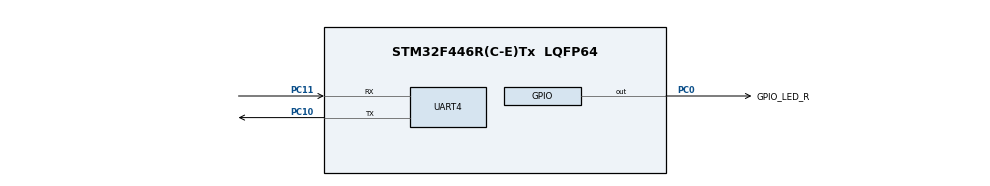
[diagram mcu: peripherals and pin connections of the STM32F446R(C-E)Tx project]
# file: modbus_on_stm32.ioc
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Dma.Request0=UART4_RX
Dma.Request1=UART4_TX
Dma.UART4_RX.0.Direction=DMA_PERIPH_TO_MEMORY
Dma.UART4_RX.0.FIFOMode=DMA_FIFOMODE_DISABLE
Dma.UART4_RX.0.Instance=DMA1_Stream2
Dma.UART4_RX.0.MemDataAlignment=DMA_MDATAALIGN_BYTE
Dma.UART4_RX.0.MemInc=DMA_MINC_ENABLE
Dma.UART4_RX.0.Mode=DMA_NORMAL
Dma.UART4_RX.0.PeriphDataAlignment=DMA_PDATAALIGN_BYTE
Dma.UART4_RX.0.PeriphInc=DMA_PINC_DISABLE
Dma.UART4_RX.0.Priority=DMA_PRIORITY_VERY_HIGH
Dma.UART4_TX.1.Direction=DMA_MEMORY_TO_PERIPH
Dma.UART4_TX.1.FIFOMode=DMA_FIFOMODE_DISABLE
Dma.UART4_TX.1.Instance=DMA1_Stream4
Dma.UART4_TX.1.MemDataAlignment=DMA_MDATAALIGN_BYTE
Dma.UART4_TX.1.MemInc=DMA_MINC_ENABLE
Dma.UART4_TX.1.Mode=DMA_NORMAL
Dma.UART4_TX.1.PeriphDataAlignment=DMA_PDATAALIGN_BYTE
Dma.UART4_TX.1.PeriphInc=DMA_PINC_DISABLE
Dma.UART4_TX.1.Priority=DMA_PRIORITY_VERY_HIGH
Mcu.Family=STM32F4
Mcu.Name=STM32F446R(C-E)Tx
Mcu.Package=LQFP64
NVIC.DMA1_Stream2_IRQn=true\:0\:0\:false\:false\:true\:false\:true\:true
NVIC.DMA1_Stream4_IRQn=true\:0\:0\:false\:false\:true\:false\:true\:true
NVIC.PriorityGroup=NVIC_PRIORITYGROUP_4
NVIC.TIM1_UP_TIM10_IRQn=true\:15\:0\:true\:false\:true\:true\:true\:true
NVIC.UART4_IRQn=true\:0\:0\:false\:false\:true\:true\:true\:true
PC0.GPIO_Label=GPIO_LED_R
PC0.Signal=GPIO_Output
PC10.Mode=Asynchronous
PC10.Signal=UART4_TX
PC11.Mode=Asynchronous
PC11.Signal=UART4_RX
PH0-OSC_IN.Mode=HSE-External-Oscillator
PH0-OSC_IN.Signal=RCC_OSC_IN
PH1-OSC_OUT.Mode=HSE-External-Oscillator
PH1-OSC_OUT.Signal=RCC_OSC_OUT
ProjectManager.HeapSize=0x200
ProjectManager.StackSize=0x400
ProjectManager.TargetToolchain=MDK-ARM V5.32
RCC.CortexFreq_Value=16000000
RCC.USBFreq_Value=96000000
RCC.VCOOutputFreq_Value=192000000
TIM1.Period=4999
TIM1.Prescaler=1599
UART4.VirtualMode=Asynchronous
VP_TIM1_VS_ClockSourceINT.Mode=Internal
board=custom

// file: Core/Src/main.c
/* USER CODE BEGIN Header */
/**
  ******************************************************************************
  * @file           : main.c
  * @brief          : Main program body
  ******************************************************************************
  * @attention
  *
  * Copyright (c) 2024 STMicroelectronics.
  * All rights reserved.
  *
  * This software is licensed under terms that can be found in the LICENSE file
  * in the root directory of this software component.
  * If no LICENSE file comes with this software, it is provided AS-IS.
  *
  ******************************************************************************
  */
/* USER CODE END Header */
#include "main.h"

/* USER CODE BEGIN Includes */
#include "string.h"
/* USER CODE END Includes */

/* USER CODE BEGIN PD */
#define MAX_BUFF_SIZE 256
/* USER CODE END PD */

TIM_HandleTypeDef htim1;

UART_HandleTypeDef huart4;
DMA_HandleTypeDef hdma_uart4_rx;
DMA_HandleTypeDef hdma_uart4_tx;

/* USER CODE BEGIN PV */
uint8_t rxbuff[MAX_BUFF_SIZE];
uint8_t txbuff[MAX_BUFF_SIZE];
/* USER CODE END PV */

void SystemClock_Config(void);
static void MX_GPIO_Init(void);
static void MX_DMA_Init(void);
static void MX_UART4_Init(void);
static void MX_TIM1_Init(void);
/* USER CODE BEGIN PFP */
void HAL_UARTEx_RxEventCallback(UART_HandleTypeDef *huart, uint16_t Size);
/* USER CODE END PFP */

int main(void)
{

  /* MCU Configuration--------------------------------------------------------*/

  /* Reset of all peripherals, Initializes the Flash interface and the Systick. */
  HAL_Init();

  /* Configure the system clock */
  SystemClock_Config();

  /* Initialize all configured peripherals */
  MX_GPIO_Init();
  MX_DMA_Init();
  MX_UART4_Init();
  MX_TIM1_Init();
  /* USER CODE BEGIN 2 */
	HAL_TIM_Base_Start_IT(&htim1);
	uint8_t ch = 1;
	uint8_t led_status = 1;
	HAL_GPIO_WritePin(GPIO_LED_R_GPIO_Port, GPIO_LED_R_Pin, led_status);

	HAL_UARTEx_ReceiveToIdle_DMA(&huart4, rxbuff, 256);
	__HAL_DMA_DISABLE_IT(&hdma_uart4_rx, DMA_IT_HT);
  /* USER CODE END 2 */

  /* Infinite loop */
  while (1)
  {

  }
}

void SystemClock_Config(void)
{
  RCC_OscInitTypeDef RCC_OscInitStruct = {0};
  RCC_ClkInitTypeDef RCC_ClkInitStruct = {0};

  /** Configure the main internal regulator output voltage
  */
  __HAL_RCC_PWR_CLK_ENABLE();
  __HAL_PWR_VOLTAGESCALING_CONFIG(PWR_REGULATOR_VOLTAGE_SCALE3);

  /** Initializes the RCC Oscillators according to the specified parameters
  * in the RCC_OscInitTypeDef structure.
  */
  RCC_OscInitStruct.OscillatorType = RCC_OSCILLATORTYPE_HSI;
  RCC_OscInitStruct.HSIState = RCC_HSI_ON;
  RCC_OscInitStruct.HSICalibrationValue = RCC_HSICALIBRATION_DEFAULT;
  RCC_OscInitStruct.PLL.PLLState = RCC_PLL_NONE;
  if (HAL_RCC_OscConfig(&RCC_OscInitStruct) != HAL_OK)
  {
    Error_Handler();
  }

  /** Initializes the CPU, AHB and APB buses clocks
  */
  RCC_ClkInitStruct.ClockType = RCC_CLOCKTYPE_HCLK|RCC_CLOCKTYPE_SYSCLK
                              |RCC_CLOCKTYPE_PCLK1|RCC_CLOCKTYPE_PCLK2;
  RCC_ClkInitStruct.SYSCLKSource = RCC_SYSCLKSOURCE_HSI;
  RCC_ClkInitStruct.AHBCLKDivider = RCC_SYSCLK_DIV1;
  RCC_ClkInitStruct.APB1CLKDivider = RCC_HCLK_DIV1;
  RCC_ClkInitStruct.APB2CLKDivider = RCC_HCLK_DIV1;

  if (HAL_RCC_ClockConfig(&RCC_ClkInitStruct, FLASH_LATENCY_0) != HAL_OK)
  {
    Error_Handler();
  }
}

static void MX_TIM1_Init(void)
{

  TIM_ClockConfigTypeDef sClockSourceConfig = {0};
  TIM_MasterConfigTypeDef sMasterConfig = {0};

  htim1.Instance = TIM1;
  htim1.Init.Prescaler = 1599;
  htim1.Init.CounterMode = TIM_COUNTERMODE_UP;
  htim1.Init.Period = 4999;
  htim1.Init.ClockDivision = TIM_CLOCKDIVISION_DIV1;
  htim1.Init.RepetitionCounter = 0;
  htim1.Init.AutoReloadPreload = TIM_AUTORELOAD_PRELOAD_DISABLE;
  if (HAL_TIM_Base_Init(&htim1) != HAL_OK)
  {
    Error_Handler();
  }
  sClockSourceConfig.ClockSource = TIM_CLOCKSOURCE_INTERNAL;
  if (HAL_TIM_ConfigClockSource(&htim1, &sClockSourceConfig) != HAL_OK)
  {
    Error_Handler();
  }
  sMasterConfig.MasterOutputTrigger = TIM_TRGO_RESET;
  sMasterConfig.MasterSlaveMode = TIM_MASTERSLAVEMODE_DISABLE;
  if (HAL_TIMEx_MasterConfigSynchronization(&htim1, &sMasterConfig) != HAL_OK)
  {
    Error_Handler();
  }

}

static void MX_UART4_Init(void)
{

  huart4.Instance = UART4;
  huart4.Init.BaudRate = 115200;
  huart4.Init.WordLength = UART_WORDLENGTH_8B;
  huart4.Init.StopBits = UART_STOPBITS_1;
  huart4.Init.Parity = UART_PARITY_NONE;
  huart4.Init.Mode = UART_MODE_TX_RX;
  huart4.Init.HwFlowCtl = UART_HWCONTROL_NONE;
  huart4.Init.OverSampling = UART_OVERSAMPLING_16;
  if (HAL_UART_Init(&huart4) != HAL_OK)
  {
    Error_Handler();
  }

}

static void MX_DMA_Init(void)
{

  /* DMA controller clock enable */
  __HAL_RCC_DMA1_CLK_ENABLE();

  /* DMA interrupt init */
  /* DMA1_Stream2_IRQn interrupt configuration */
  HAL_NVIC_SetPriority(DMA1_Stream2_IRQn, 0, 0);
  HAL_NVIC_EnableIRQ(DMA1_Stream2_IRQn);
  /* DMA1_Stream4_IRQn interrupt configuration */
  HAL_NVIC_SetPriority(DMA1_Stream4_IRQn, 0, 0);
  HAL_NVIC_EnableIRQ(DMA1_Stream4_IRQn);

}

static void MX_GPIO_Init(void)
{
  GPIO_InitTypeDef GPIO_InitStruct = {0};

  /* GPIO Ports Clock Enable */
  __HAL_RCC_GPIOH_CLK_ENABLE();
  __HAL_RCC_GPIOC_CLK_ENABLE();

  /*Configure GPIO pin Output Level */
  HAL_GPIO_WritePin(GPIO_LED_R_GPIO_Port, GPIO_LED_R_Pin, GPIO_PIN_RESET);

  /*Configure GPIO pin : GPIO_LED_R_Pin */
  GPIO_InitStruct.Pin = GPIO_LED_R_Pin;
  GPIO_InitStruct.Mode = GPIO_MODE_OUTPUT_PP;
  GPIO_InitStruct.Pull = GPIO_NOPULL;
  GPIO_InitStruct.Speed = GPIO_SPEED_FREQ_LOW;
  HAL_GPIO_Init(GPIO_LED_R_GPIO_Port, &GPIO_InitStruct);

}

/* USER CODE BEGIN 4 */
void HAL_UARTEx_RxEventCallback(UART_HandleTypeDef *huart, uint16_t Size)
{
	uint8_t cnt = MAX_BUFF_SIZE - __HAL_DMA_GET_COUNTER(&hdma_uart4_rx);
	memset(txbuff, 0, sizeof(txbuff));
	memcpy(txbuff, rxbuff, cnt);
	HAL_UART_Transmit_DMA(&huart4, txbuff, cnt);

	HAL_UARTEx_ReceiveToIdle_DMA(&huart4, rxbuff, MAX_BUFF_SIZE);
	__HAL_DMA_DISABLE_IT(&hdma_uart4_rx, DMA_IT_HT);
}

void HAL_TIM_PeriodElapsedCallback(TIM_HandleTypeDef* htim)
{
	if (htim == &htim1)
	{
		// HAL_GPIO_TogglePin(GPIO_LED_R_GPIO_Port, GPIO_LED_R_Pin);
	}
}
/* USER CODE END 4 */

void Error_Handler(void)
{
  __disable_irq();
  while (1)
  {
  }
}
